# LM3S6965 register map
Vendor: Texas Instruments; File version: 1.0
CPU: CM3 r2p0, little endian, MPU, no FPU, 3 interrupt priority bits
Registers are 32-bit, read-write, reset 0x0 unless marked. A register's access mark holds for its fields unless they carry their own. Offsets are from the block's base; [hi:lo] are bit positions; {n}, {i} and the like mark numbered series; 'fields as' and 'values as' point back to an identical list.

## UART0 — Универсальный асинхронный приёмопередатчик (PL011)
Base 0x4000C000
Same registers: UART1 0x4000D000
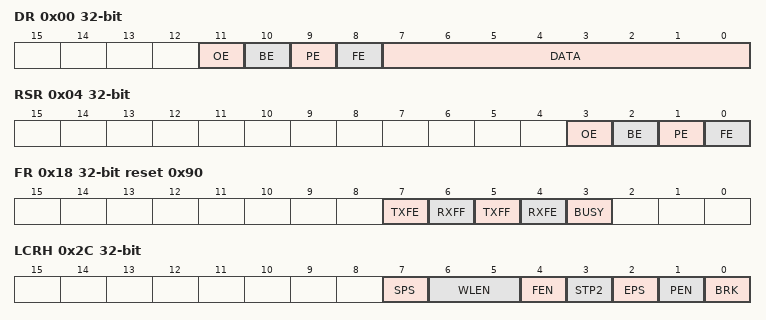
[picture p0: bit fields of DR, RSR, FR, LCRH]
0x00 DR — Данные: запись — в FIFO передатчика, чтение — из FIFO приёмника с флагами ошибок
  [11] OE ro — Переполнение приёмника
  [10] BE ro — Разрыв линии
  [9] PE ro — Ошибка чётности
  [8] FE ro — Ошибка кадра
  [7:0] DATA — Байт данных
0x04 RSR — Состояние приёма; запись сбрасывает ошибки (UARTECR)
  [3] OE — Переполнение приёмника
  [2] BE — Разрыв линии
  [1] PE — Ошибка чётности
  [0] FE — Ошибка кадра
0x18 FR ro reset 0x90 — Флаги
  [7] TXFE — FIFO передатчика пуст
  [6] RXFF — FIFO приёмника полон
  [5] TXFF — FIFO передатчика полон
  [4] RXFE — FIFO приёмника пуст
  [3] BUSY — Передатчик занят
0x20 ILPR — Делитель IrDA для режима низкого потребления
  [7:0] ILPDVSR — Делитель
0x24 IBRD — Целая часть делителя скорости
  [15:0] DIVINT — Целая часть
0x28 FBRD — Дробная часть делителя скорости
  [5:0] DIVFRAC — Дробная часть, 1/64
0x2C LCRH — Формат кадра
  [7] SPS — Фиксированная чётность
  [6:5] WLEN — Длина слова: 0 — 5 бит … 3 — 8 бит
  [4] FEN — FIFO включены
  [3] STP2 — Два стоповых бита
  [2] EPS — Чётность — чётная
  [1] PEN — Чётность включена
  [0] BRK — Послать разрыв
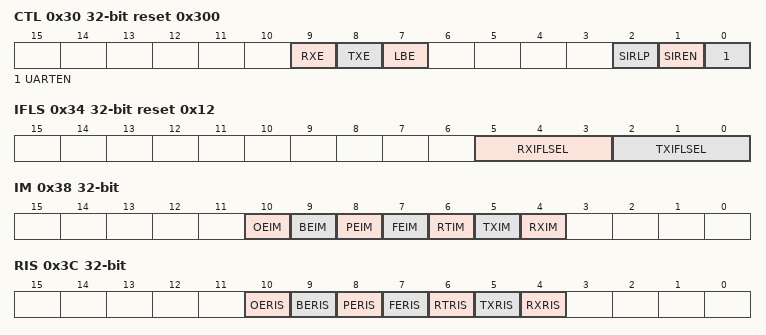
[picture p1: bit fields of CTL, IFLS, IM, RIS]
0x30 CTL reset 0x300 — Управление
  [9] RXE — Приёмник включён
  [8] TXE — Передатчик включён
  [7] LBE — Петля
  [2] SIRLP — IrDA низкого потребления
  [1] SIREN — IrDA включён
  [0] UARTEN — UART включён
0x34 IFLS reset 0x12 — Пороги прерываний FIFO
  [5:3] RXIFLSEL — Порог приёмника
  [2:0] TXIFLSEL — Порог передатчика
0x38 IM — Маска прерываний
  [10] OEIM, [9] BEIM, [8] PEIM, [7] FEIM, [6] RTIM, [5] TXIM, [4] RXIM
0x3C RIS ro — Сырые запросы прерываний
  [10] OERIS, [9] BERIS, [8] PERIS, [7] FERIS, [6] RTRIS, [5] TXRIS, [4] RXRIS
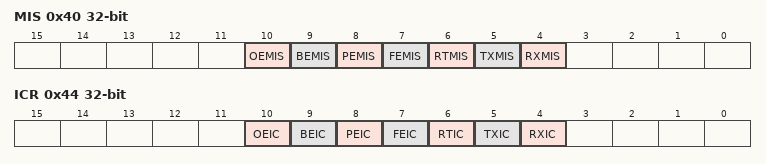
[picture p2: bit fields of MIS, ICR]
0x40 MIS ro — Запросы прерываний после маски
  [10] OEMIS, [9] BEMIS, [8] PEMIS, [7] FEMIS, [6] RTMIS, [5] TXMIS, [4] RXMIS
0x44 ICR wo — Сброс запросов прерываний: 1 сбрасывает бит
  [10] OEIC, [9] BEIC, [8] PEIC, [7] FEIC, [6] RTIC, [5] TXIC, [4] RXIC

## TIMER0 — Таймер общего назначения (GPTM)
Base 0x40030000
Same registers: TIMER1 0x40031000, TIMER2 0x40032000, TIMER3 0x40033000
0x00 CFG — Конфигурация: 32-битный таймер или два 16-битных
  [2:0] GPTMCFG — Режим
    0=BITS32 (Один 32-битный таймер); 1=RTC (32-битные часы реального времени); 4=BITS16 (Два 16-битных таймера)
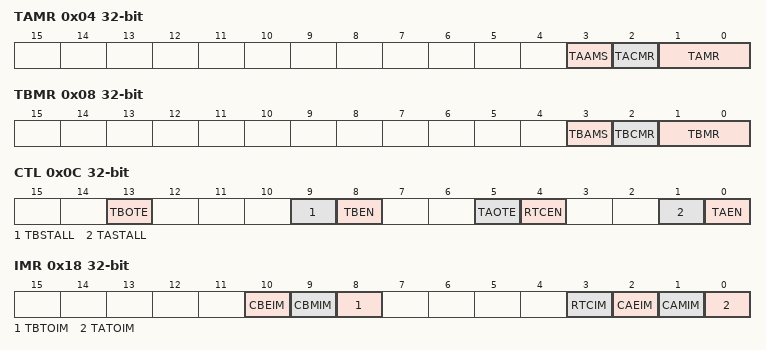
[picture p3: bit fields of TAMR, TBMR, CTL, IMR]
0x04 TAMR — Режим таймера A
  [3] TAAMS — Режим ШИМ
  [2] TACMR — Захват по времени
  [1:0] TAMR — Режим
    1=ONE_SHOT (Однократный); 2=PERIODIC (Периодический); 3=CAPTURE (Захват)
0x08 TBMR — Режим таймера B
  [3] TBAMS — Режим ШИМ
  [2] TBCMR — Захват по времени
  [1:0] TBMR — Режим
    values as TAMR.TAMR
0x0C CTL — Управление
  [13] TBOTE — Таймер B запускает АЦП
  [9] TBSTALL — Таймер B стоит при остановке отладчиком
  [8] TBEN — Таймер B включён
  [5] TAOTE — Таймер A запускает АЦП
  [4] RTCEN — Часы реального времени при остановке
  [1] TASTALL — Таймер A стоит при остановке отладчиком
  [0] TAEN — Таймер A включён
0x18 IMR — Маска прерываний: 1 — прерывание разрешено
  [10] CBEIM — Событие захвата B
  [9] CBMIM — Совпадение захвата B
  [8] TBTOIM — Таймер B досчитал
  [3] RTCIM — Часы реального времени
  [2] CAEIM — Событие захвата A
  [1] CAMIM — Совпадение захвата A
  [0] TATOIM — Таймер A досчитал
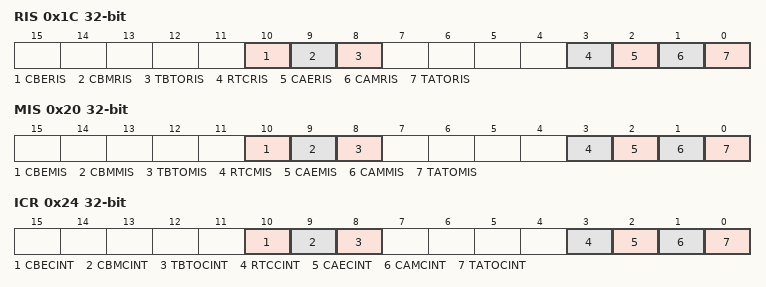
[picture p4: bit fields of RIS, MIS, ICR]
0x1C RIS ro — Необработанные запросы прерываний
  [10] CBERIS, [9] CBMRIS, [8] TBTORIS, [3] RTCRIS, [2] CAERIS, [1] CAMRIS, [0] TATORIS
0x20 MIS ro — Запросы прерываний после маски
  [10] CBEMIS, [9] CBMMIS, [8] TBTOMIS, [3] RTCMIS, [2] CAEMIS, [1] CAMMIS, [0] TATOMIS
0x24 ICR wo — Сброс запросов прерываний: 1 сбрасывает бит
  [10] CBECINT, [9] CBMCINT, [8] TBTOCINT, [3] RTCCINT, [2] CAECINT, [1] CAMCINT, [0] TATOCINT
0x28 TAILR reset 0xFFFFFFFF — Начальное значение таймера A: период в тактах минус один
0x2C TBILR reset 0xFFFF — Начальное значение таймера B
  [15:0] TBILR
0x30 TAMATCHR reset 0xFFFFFFFF — Совпадение таймера A
  [31:0] TAMR
0x34 TBMATCHR reset 0xFFFF — Совпадение таймера B
  [15:0] TBMR
0x38 TAPR — Предделитель таймера A
  [7:0] TAPSR
0x3C TBPR — Предделитель таймера B
  [7:0] TBPSR
0x48 TAR ro reset 0xFFFFFFFF — Текущее значение таймера A
0x4C TBR ro reset 0xFFFF — Текущее значение таймера B
  [15:0] TBR

## ADC0 — Аналого-цифровой преобразователь, 10 бит
Base 0x40038000
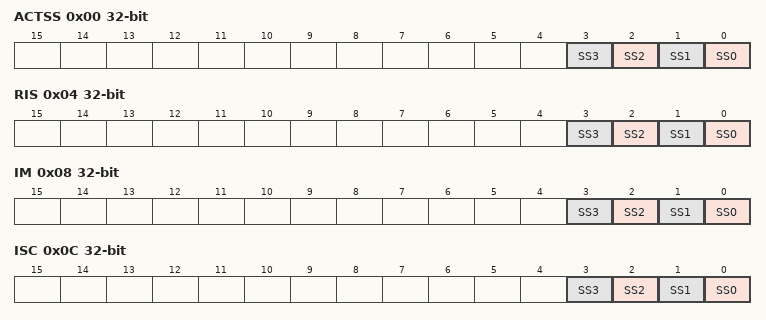
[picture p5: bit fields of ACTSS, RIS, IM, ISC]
0x00 ACTSS — Включённые последовательности выборки
  [n] SS{n} (n=0..3) — Последовательность включена
0x04 RIS ro — Необработанные запросы прерываний
  [n] SS{n} (n=0..3) — Последовательность закончила выборку
0x08 IM — Маска прерываний
  [n] SS{n} (n=0..3) — Прерывание разрешено
0x0C ISC — Запросы после маски; запись 1 сбрасывает запрос
  [n] SS{n} (n=0..3) — Запрос есть; 1 — сбросить
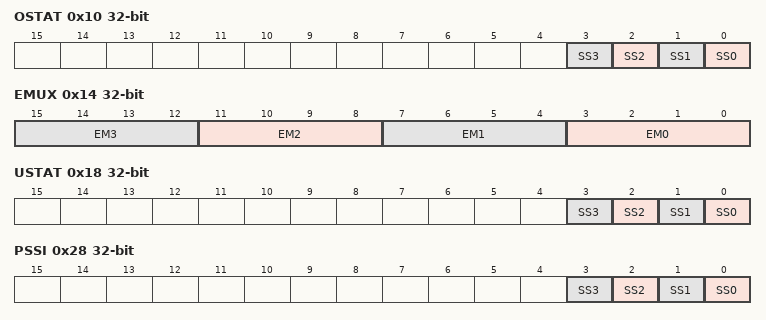
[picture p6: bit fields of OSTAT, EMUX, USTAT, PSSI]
0x10 OSTAT — Переполнение FIFO
  [n] SS{n} (n=0..3) — FIFO переполнено; 1 — сбросить
0x14 EMUX — Источник запуска каждой последовательности
  [4n+3:4n] EM{n} (n=0..3) — Запуск последовательности
    0=PROCESSOR (Программный запуск через PSSI); 1=COMP0 (Аналоговый компаратор 0); 2=COMP1 (Аналоговый компаратор 1); 4=EXTERNAL (Внешний сигнал GPIO PB4); 5=TIMER (Таймер с битом TnOTE); 6=PWM0 (ШИМ 0); 7=PWM1 (ШИМ 1); 8=PWM2 (ШИМ 2); 15=ALWAYS (Непрерывно)
0x18 USTAT — Опустошение FIFO
  [n] SS{n} (n=0..3) — FIFO опустошено; 1 — сбросить
0x28 PSSI wo — Программный запуск последовательностей
  [n] SS{n} (n=0..3) — Запустить последовательность
0xA0 SSMUX3 — Последовательность 3: номер входа
  [1:0] MUX0 — Вход АЦП
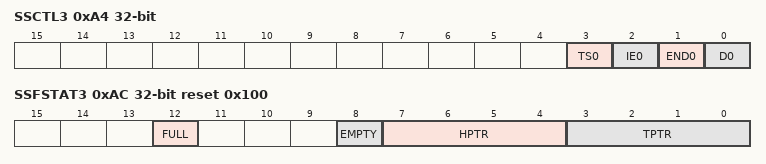
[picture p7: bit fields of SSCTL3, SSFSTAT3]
0xA4 SSCTL3 — Последовательность 3: управление выборкой
  [3] TS0 — Датчик температуры вместо входа
  [2] IE0 — Прерывание после выборки
  [1] END0 — Последняя выборка последовательности
  [0] D0 — Дифференциальный вход
0xA8 SSFIFO3 ro — Последовательность 3: результат из FIFO
  [9:0] DATA — Результат преобразования
0xAC SSFSTAT3 ro reset 0x100 — Последовательность 3: состояние FIFO
  [12] FULL — Полно
  [8] EMPTY — Пусто
  [7:4] HPTR — Голова
  [3:0] TPTR — Хвост
